VERSION ""

NS_ :

BS_:

BU_:
VAL_TABLE_ vt_BNRaccuracy 1 "DegradedAccuracy" 0 "NominalAccuracy" ;
VAL_TABLE_ vt_BCDstatus_above_below 3 "Below" 2 "FT" 1 "NCD" 0 "Above" ;
VAL_TABLE_ vt_BCDstatus_to_from 3 "From" 2 "FT" 1 "NCD" 0 "To" ;
VAL_TABLE_ vt_BCDstatus_right_left 3 "Left" 2 "FT" 1 "NCD" 0 "Right" ;
VAL_TABLE_ vt_BCDstatus_east_west 3 "West" 2 "FT" 1 "NCD" 0 "East" ;
VAL_TABLE_ vt_BCDstatus_north_south 3 "South" 2 "FT" 1 "NCD" 0 "North" ;
VAL_TABLE_ vt_BCDstatus_plus_minus 3 "Minus" 2 "FT" 1 "NCD" 0 "Plus" ;
VAL_TABLE_ vt_DSCstatus 3 "FW" 2 "FT" 1 "NCD" 0 "NO" ;
VAL_TABLE_ vt_BNRsign_above_below 1 "Below" 0 "Above" ;
VAL_TABLE_ vt_BNRsign_to_from 1 "From" 0 "To" ;
VAL_TABLE_ vt_BNRsign_right_left 1 "Left" 0 "Right" ;
VAL_TABLE_ vt_BNRsign_east_west 1 "West" 0 "East" ;
VAL_TABLE_ vt_BNRsign_north_south 1 "South" 0 "North" ;
VAL_TABLE_ vt_BNRsign_plus_minus 1 "Minus" 0 "Plus" ;
VAL_TABLE_ vt_BNRstatus 3 "NO" 2 "FT" 1 "NCD" 0 "FW" ;

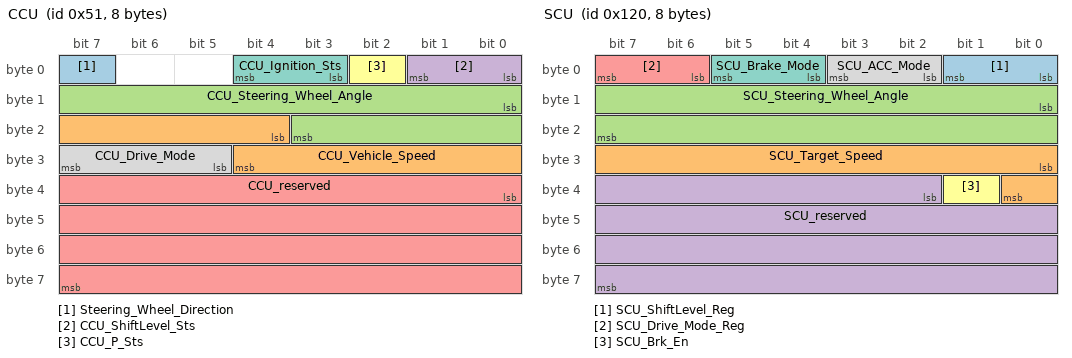
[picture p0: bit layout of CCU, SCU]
BO_ 81 CCU: 8 Vector__XXX
 SG_ Steering_Wheel_Direction : 7|1@1+ (1,0) [0|1] "" Vector__XXX
 SG_ CCU_Vehicle_Speed : 20|9@1+ (0.1,0) [0|51] "" Vector__XXX
 SG_ CCU_Steering_Wheel_Angle : 8|12@1+ (0.1,0) [0|409.5] "" Vector__XXX
 SG_ CCU_ShiftLevel_Sts : 0|2@1+ (1,0) [0|3] "" Vector__XXX
 SG_ CCU_reserved : 32|32@1+ (1,0) [0|0] "" Vector__XXX
 SG_ CCU_P_Sts : 2|1@1+ (1,0) [0|1] "" Vector__XXX
 SG_ CCU_Ignition_Sts : 3|2@1+ (1,0) [0|1] "" Vector__XXX
 SG_ CCU_Drive_Mode : 29|3@1+ (1,0) [0|3] "" Vector__XXX

BO_ 288 SCU: 8 Vector__XXX
 SG_ SCU_ShiftLevel_Reg : 0|2@1+ (1,0) [0|3] "" Vector__XXX
 SG_ SCU_Target_Speed : 24|9@1+ (0.1,0) [0|51] "km/h" Vector__XXX
 SG_ SCU_Steering_Wheel_Angle : 8|16@1- (0.1,0) [-120|120] "" Vector__XXX
 SG_ SCU_reserved : 34|30@1+ (1,0) [0|1.84467440737096E+19] "" Vector__XXX
 SG_ SCU_Drive_Mode_Reg : 6|2@1+ (1,0) [0|3] "" Vector__XXX
 SG_ SCU_Brk_En : 33|1@1+ (1,0) [0|1] "" Vector__XXX
 SG_ SCU_Brake_Mode : 4|2@1+ (1,0) [0|3] "" Vector__XXX
 SG_ SCU_ACC_Mode : 2|2@1+ (1,0) [0|3] "" Vector__XXX

BA_DEF_  "TemplateVersion" STRING ;
BA_DEF_  "ProtocolType" STRING ;
BA_DEF_ BO_  "A429SpecSource" ENUM  "ARINC","GAMA","Private";
BA_DEF_ BO_  "A429Protocol" ENUM  "BC","AIM","A619","WB1","WB2","WB3";
BA_DEF_  "A429Parity" ENUM  "unknown","odd","even";
BA_DEF_ BU_  "A429Equipment" STRING ;
BA_DEF_  "Baudrate" INT 10500 110000;
BA_DEF_  "ToolName" STRING ;
BA_DEF_  "ToolVersion" STRING ;
BA_DEF_  "Manufacturer" STRING ;
BA_DEF_  "VersionDay" INT 0 31;
BA_DEF_  "VersionMonth" INT 0 12;
BA_DEF_  "VersionWeek" INT 0 0;
BA_DEF_  "BusType" STRING ;
BA_DEF_DEF_  "TemplateVersion" "1.1.0.0";
BA_DEF_DEF_  "ProtocolType" "Aerospace";
BA_DEF_DEF_  "A429SpecSource" "ARINC";
BA_DEF_DEF_  "A429Protocol" "BC";
BA_DEF_DEF_  "A429Parity" "odd";
BA_DEF_DEF_  "A429Equipment" "<unknown>";
BA_DEF_DEF_  "Baudrate" 100000;
BA_DEF_DEF_  "ToolName" "manually";
BA_DEF_DEF_  "ToolVersion" "x.y.z.n";
BA_DEF_DEF_  "Manufacturer" "<unknown>";
BA_DEF_DEF_  "VersionDay" 1;
BA_DEF_DEF_  "VersionMonth" 1;
BA_DEF_DEF_  "VersionWeek" 1;
BA_DEF_DEF_  "BusType" "ARINC429";
BA_ "BusType" "CAN";
